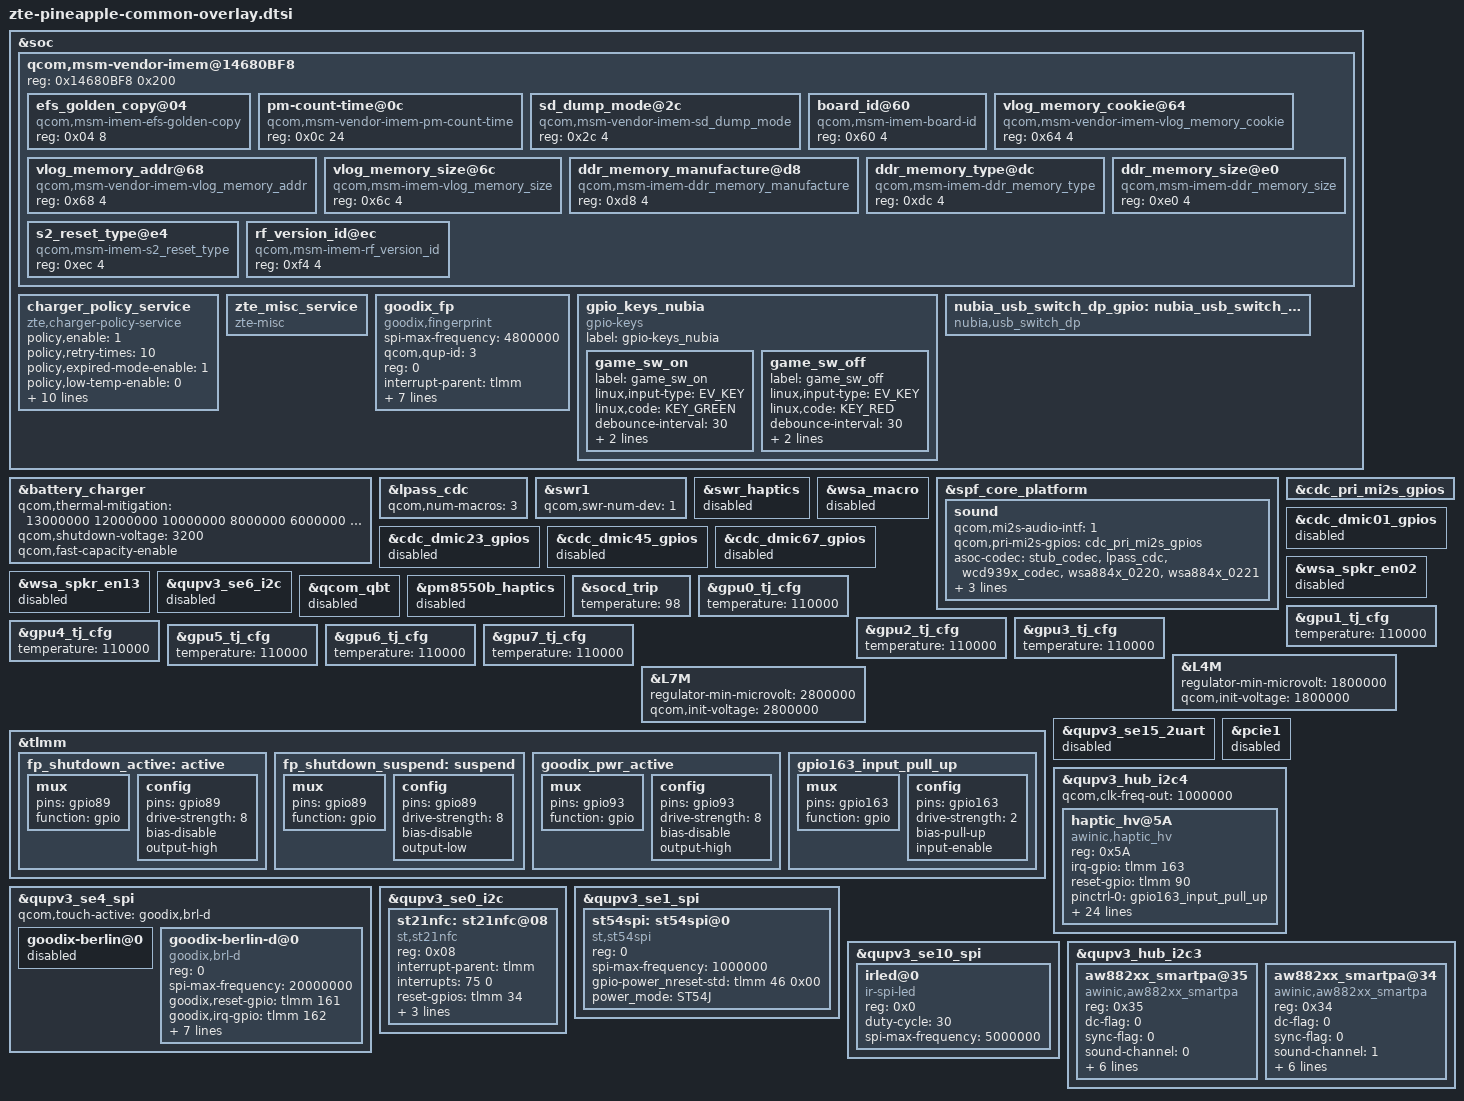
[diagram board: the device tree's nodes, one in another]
#include <dt-bindings/input/input.h>

&soc {
	qcom,msm-vendor-imem@14680BF8 {
        reg = <0x14680BF8 0x200>; /* Address and size of IMEM */
		ranges = <0x0 0x14680BF8 0x200>;
		#address-cells = <1>;
		#size-cells = <1>;

		efs_golden_copy@04 {
			compatible = "qcom,msm-imem-efs-golden-copy";
			reg = <0x04 8>;
		};

		pm-count-time@0c {
			compatible = "qcom,msm-vendor-imem-pm-count-time";
			reg = <0x0c 24>;
		};

		sd_dump_mode@2c {
			compatible = "qcom,msm-vendor-imem-sd_dump_mode";
			reg = <0x2c 4>;
		};

		board_id@60 {
			compatible = "qcom,msm-imem-board-id";
			reg = <0x60 4>;
		};

		vlog_memory_cookie@64 {
			compatible = "qcom,msm-vendor-imem-vlog_memory_cookie";
			reg = <0x64 4>;
		};

		vlog_memory_addr@68 {
			compatible = "qcom,msm-vendor-imem-vlog_memory_addr";
			reg = <0x68 4>;
		};

		vlog_memory_size@6c {
			compatible = "qcom,msm-imem-vlog_memory_size";
			reg = <0x6c 4>;
		};

		ddr_memory_manufacture@d8 {
			compatible = "qcom,msm-imem-ddr_memory_manufacture";
			reg = <0xd8 4>;
		};

		ddr_memory_type@dc {
			compatible = "qcom,msm-imem-ddr_memory_type";
			reg = <0xdc 4>;
		};

		ddr_memory_size@e0 {
			compatible = "qcom,msm-imem-ddr_memory_size";
			reg = <0xe0 4>;
		};

		s2_reset_type@e4 {
			compatible = "qcom,msm-imem-s2_reset_type";
			reg = <0xec 4>;
		};

		rf_version_id@ec {
			compatible = "qcom,msm-imem-rf_version_id";
			reg = <0xf4 4>;
		};
	};

	charger_policy_service {
		compatible = "zte,charger-policy-service";
		status="okay";
		policy,enable = <1>;
		policy,retry-times = <10>;
		policy,expired-mode-enable = <1>;
		policy,low-temp-enable = <0>;
		policy,have-power-path = <1>;
		policy,timeout-seconds = <64800>;/* 18 hours */
		policy,expired-max-capacity = <90>;
		policy,expired-min-capacity = <70>;
		policy,demo-max-capacity = <90>;
		policy,demo-min-capacity = <70>;
		policy,no-powerpath-delta-capacity = <10>;
		policy,battery-phy-name = "battery";
		policy,interface-phy-name = "interface";
		policy,cas-phy-name = "cas";
	};

	zte_misc_service {
		compatible = "zte-misc";
		status="okay";
	};
};

&battery_charger {
	/* external thermal-mitigation for different case,each case 10 levels,base is level=1
	usb screen off
	usb screen on 
	wls screen on
	wls screen off*/
	qcom,thermal-mitigation = <13000000 12000000 10000000 8000000 6000000 5000000 4000000 2000000 1500000 1000000
								10000000 8000000 6000000 5000000 4000000 3000000 2000000 1500000 1000000 800000
								10000000 8000000 6000000 4000000 3000000 2000000 1500000 1000000 500000 300000
								 8000000 6000000 5000000 1000000 1000000 1000000  800000  500000 500000 300000
								>;
	qcom,shutdown-voltage = <3200>;
	/* enable fast_capacity */
	qcom,fast-capacity-enable;
};

&lpass_cdc {
	qcom,num-macros = <3>;
};

&swr1 {
	qcom,swr-num-dev = <1>;
};

&swr_haptics {
	status = "disabled";
};

&wsa_macro {
	status = "disabled";
};

&spf_core_platform {
	sound {
		qcom,mi2s-audio-intf = <1>;
		qcom,pri-mi2s-gpios = <&cdc_pri_mi2s_gpios>;

		asoc-codec = <&stub_codec>, <&lpass_cdc>,
			     <&wcd939x_codec>,
			     <&wsa884x_0220>, <&wsa884x_0221>;
		asoc-codec-names = "msm-stub-codec.1", "lpass-cdc",
				   "wcd939x_codec",
				   "wsa-codec1", "wsa-codec2";
		qcom,wsa-max-devs = <0>;
	};
};

&cdc_pri_mi2s_gpios {
	status = "okay";
};

&cdc_dmic01_gpios {
	status = "disabled";
};

&cdc_dmic23_gpios {
	status = "disabled";
};

&cdc_dmic45_gpios {
	status = "disabled";
};

&cdc_dmic67_gpios {
	status = "disabled";
};

&wsa_spkr_en02 {
	status = "disabled";
};

&wsa_spkr_en13 {
	status = "disabled";
};

&qupv3_se6_i2c {
	status = "disabled";
};

&qcom_qbt {
	status = "disabled";
};

&pm8550b_haptics {
	status = "disabled";
};

&socd_trip {
	temperature = <98>;
};

&gpu0_tj_cfg {
	temperature = <110000>;
};

&gpu1_tj_cfg {
	temperature = <110000>;
};

&gpu2_tj_cfg {
	temperature = <110000>;
};

&gpu3_tj_cfg {
	temperature = <110000>;
};

&gpu4_tj_cfg {
	temperature = <110000>;
};

&gpu5_tj_cfg {
	temperature = <110000>;
};

&gpu6_tj_cfg {
	temperature = <110000>;
};

&gpu7_tj_cfg {
	temperature = <110000>;
};

&L4M {
	regulator-min-microvolt = <1800000>;
	qcom,init-voltage = <1800000>;
};

&L7M {
	regulator-min-microvolt = <2800000>;
	qcom,init-voltage = <2800000>;
};

&tlmm {
	fp_shutdown_active: active{
		mux {
			pins = "gpio89";
			function = "gpio";
		};

		config {
			pins = "gpio89";
			drive-strength = <8>;
			bias-disable;
			output-high;
		};
	};

	fp_shutdown_suspend: suspend{
		mux {
			pins = "gpio89";
			function = "gpio";
		};

		config {
			pins = "gpio89";
			drive-strength = <8>;
			bias-disable;
			output-low;
		};
	};

	goodix_pwr_active: goodix_pwr_active {
		mux {
			pins = "gpio93";
			function = "gpio";
		};

		config {
			pins = "gpio93";
			drive-strength = <8>;
			bias-disable;
			output-high;
		};
	};
};

&soc {
	goodix_fp {
		compatible = "goodix,fingerprint";
		spi-max-frequency = <4800000>;
		qcom,qup-id = <3>;
		reg = <0>;

		interrupt-parent = <&tlmm>;
		interrupts = <92 0x2008>;
		pinctrl-names = "goodix_active", "goodix_suspend", "pwr_active";
		pinctrl-0 = <&fp_shutdown_active>;
		pinctrl-1 = <&fp_shutdown_suspend>;
		pinctrl-2 = <&goodix_pwr_active>;

		fp-gpio-reset = <&tlmm 89 0x0>;
		fp-gpio-irq = <&tlmm 92 0x2008>;
		goodix,gpio_pwr = <&tlmm 93 0x1>;
		interrupt-names = "goodix_wake_up";
	};
};

&qupv3_se15_2uart {
	status = "disabled";
};

&pcie1 {
	status = "disabled";
};

&qupv3_hub_i2c4 {
	status = "ok";
	qcom,clk-freq-out = <1000000>;
	haptic_hv@5A {
		compatible = "awinic,haptic_hv";
		reg = <0x5A>;
		irq-gpio = <&tlmm 163 0>;
		reset-gpio = <&tlmm 90 0>;
		pinctrl-names = "irq_active";
		pinctrl-0 = <&gpio163_input_pull_up>;
		f0_pre = < 1700 >;
		mode = /bits/ 8 < 1 >;
		f0_cali_percent = /bits/ 8 < 7 >;
		aw8692x_max_bst_vol = /bits/ 8 < 0x7F >;
		aw8692x_cont_drv1_lvl = /bits/ 8 < 0x7F >;
		aw8692x_cont_drv2_lvl = /bits/ 8 < 0x50 >;
		aw8692x_cont_drv1_time = /bits/ 8 < 0x04 >;
		aw8692x_cont_drv2_time = /bits/ 8 < 0x06 >;
		aw8692x_cont_drv_width = /bits/ 8 < 0x6A >;
		aw8692x_cont_wait_num = /bits/ 8 < 0x06 >;
		aw8692x_cont_brk_time = /bits/ 8 < 0 >;
		aw8692x_cont_track_margin = /bits/ 8 < 0x0C >;
		aw8692x_brk_bst_md = /bits/ 8 < 0 >;
		aw8692x_cont_tset = /bits/ 8 < 0x06 >;
		aw8692x_cont_bemf_set = /bits/ 8 < 0x02 >;
		aw8692x_cont_bst_brk_gain = /bits/ 8 < 0x05 >;
		aw8692x_cont_brk_gain = /bits/ 8 < 0x08 >;
		aw8692x_duration_time = /bits/ 8 < 20 30 60 >;
		aw8692x_d2s_gain = /bits/ 8 < 0x04 >;
		aw8692x_trig_config = /bits/ 8 < 0 0 0 1 0 2 0 0
						 0 0 0 1 0 2 0 0
						 0 0 0 1 0 2 0 0 >;
		aw8692x_bst_vol_default = /bits/ 8 < 0x50 >;
		aw8692x_bst_vol_ram = /bits/ 8 < 0x50 >;
		aw8692x_bst_vol_rtp = /bits/ 8 < 0x50 >;
		/* aw8692x_is_enabled_auto_bst; */
		/* aw8692x_is_enabled_one_wire; */
	};
};

&tlmm {
	gpio163_input_pull_up: gpio163_input_pull_up {
		mux {
			pins = "gpio163";
			function = "gpio";
		};

		config {
			pins = "gpio163";
			drive-strength = <2>;
			bias-pull-up;
			input-enable;
		};
	};
};

&qupv3_se4_spi {
	qcom,touch-active = "goodix,brl-d";

	goodix-berlin@0 {
		status = "disabled";
	};

	goodix-berlin-d@0 {
		compatible = "goodix,brl-d";
		reg = <0>;
		spi-max-frequency = <20000000>;
		goodix,reset-gpio = <&tlmm 161 0x0>;
		goodix,irq-gpio = <&tlmm 162 0x0>;
		goodix,irq-flags = <2>; /* 1:trigger rising, 2:trigger falling;*/
		goodix,panel-max-x = <17856>;
		goodix,panel-max-y = <39680>;
		goodix,panel-max-w = <4080>;
		goodix,firmware-name = "goodix_firmware_9916r.bin";
		goodix,config-name = "goodix_cfg_group_9916r.bin";
	};
};

&qupv3_se0_i2c {
	status = "ok";
	/delete-node/ nq@28;
	st21nfc: st21nfc@08 {
		compatible = "st,st21nfc";
		reg = <0x08>;
		interrupt-parent = <&tlmm>;
		interrupts = <75  0>;
		reset-gpios = <&tlmm 34 0x00>;
		irq-gpios = <&tlmm 75 0x00>;
		// pidle-gpios = <&tlmm 48 0x00>;
		clkreq-gpios = <&tlmm 35 0x00>;
		//clocks = <&clock_rpmh RPMH_RF_CLK3>;
		//clock-names = "nfc_ref_clk";
		st,clk_pinctrl;
		status = "ok";
	};
};

&qupv3_se1_spi {
	status = "ok";
	st54spi: st54spi@0 {
		compatible = "st,st54spi";
		reg = <0>;
		spi-max-frequency = <1000000>;
		/* gpio used as SE_PWR_REQ or SE_nRESET */
		gpio-power_nreset-std = <&tlmm 46 0x00>;

		/* Power management mode: none, ST54H (default), ST54J */
		power_mode = "ST54J";
		status = "ok";
	};
};

&qupv3_se10_spi {
	status = "ok";
	irled@0 {
		compatible = "ir-spi-led";
		reg = <0x0>;

		duty-cycle = <30>;
		spi-max-frequency = <5000000>;
	};
};

&soc {
	gpio_keys_nubia {
		status = "okay";
		compatible = "gpio-keys";
		label = "gpio-keys_nubia";

		game_sw_on {
			label = "game_sw_on";
			linux,input-type = <EV_KEY>;
			linux,code = <KEY_GREEN>;
			debounce-interval = <30>;
			gpio-key,wakeup;
			oneshot;
		};

		game_sw_off {
			label = "game_sw_off";
			linux,input-type = <EV_KEY>;
			linux,code = <KEY_RED>;
			debounce-interval = <30>;
			gpio-key,wakeup;
			oneshot;
		};
	};

    nubia_usb_switch_dp_gpio: nubia_usb_switch_dp_gpio_ctrl {
        compatible = "nubia,usb_switch_dp";
        status = "okay";
    };
};

&qupv3_hub_i2c3 {
	status = "okay";
	/* AWINIC AW882XX Smart PA */
	aw882xx_smartpa@35 {
		compatible = "awinic,aw882xx_smartpa";
		reg = <0x35>;
		dc-flag = <0>;
		sync-flag = <0>;
		sound-channel = <0>;
		aw-tx-topo-id = <0x1000ff00>;
		aw-rx-topo-id = <0x1000ff01>;
		aw-tx-port-id = <0x1007>;
		aw-rx-port-id = <0x1006>;
		aw-re-min = <4000>;
		aw-re-max= <30000>;
		/*aw-cali-mode = "none";*/
	};
	aw882xx_smartpa@34 {
		compatible = "awinic,aw882xx_smartpa";
		reg = <0x34>;
		dc-flag = <0>;
		sync-flag = <0>;
		sound-channel = <1>;
		aw-tx-topo-id = <0x1000ff00>;
		aw-rx-topo-id = <0x1000ff01>;
		aw-tx-port-id = <0x1007>;
		aw-rx-port-id = <0x1006>;
		aw-re-min = <4000>;
		aw-re-max= <30000>;
		/*aw-cali-mode = "none";*/
	};
};
